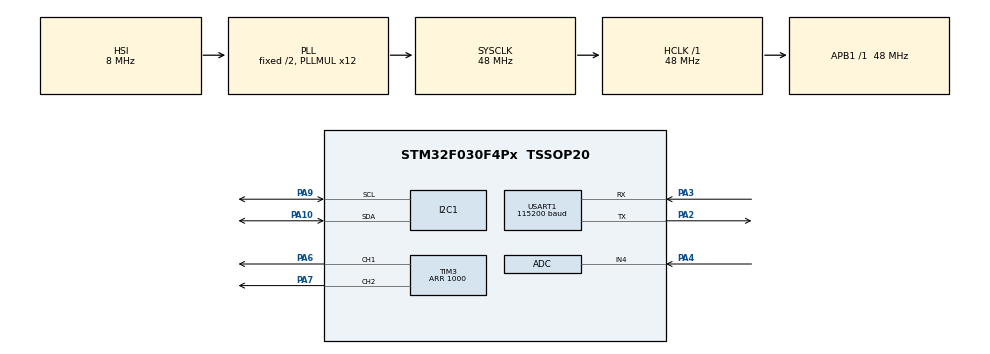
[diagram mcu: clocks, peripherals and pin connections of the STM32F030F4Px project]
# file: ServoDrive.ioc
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ADC.ContinuousConvMode=DISABLE
Dma.ADC.0.Direction=DMA_PERIPH_TO_MEMORY
Dma.ADC.0.Instance=DMA1_Channel1
Dma.ADC.0.MemDataAlignment=DMA_MDATAALIGN_HALFWORD
Dma.ADC.0.MemInc=DMA_MINC_ENABLE
Dma.ADC.0.Mode=DMA_CIRCULAR
Dma.ADC.0.PeriphDataAlignment=DMA_PDATAALIGN_HALFWORD
Dma.ADC.0.PeriphInc=DMA_PINC_DISABLE
Dma.ADC.0.Priority=DMA_PRIORITY_LOW
Dma.Request0=ADC
Mcu.Family=STM32F0
Mcu.Name=STM32F030F4Px
Mcu.Package=TSSOP20
NVIC.DMA1_Channel1_IRQn=true\:0\:0\:false\:false\:true\:false\:true\:true
NVIC.I2C1_IRQn=true\:0\:0\:false\:false\:true\:true\:true\:true
NVIC.TIM14_IRQn=true\:3\:0\:true\:false\:true\:true\:true\:true
PA10.Mode=I2C
PA10.Signal=I2C1_SDA
PA13.Mode=Serial_Wire
PA13.Signal=SYS_SWDIO
PA14.Mode=Serial_Wire
PA14.Signal=SYS_SWCLK
PA2.Mode=Asynchronous
PA2.Signal=USART1_TX
PA3.Mode=Asynchronous
PA3.Signal=USART1_RX
PA4.Mode=IN4
PA4.Signal=ADC_IN4
PA6.Signal=S_TIM3_CH1
PA7.Signal=S_TIM3_CH2
PA9.Mode=I2C
PA9.Signal=I2C1_SCL
ProjectManager.HeapSize=0x200
ProjectManager.StackSize=0x400
ProjectManager.TargetToolchain=Makefile
RCC.AHBFreq_Value=48000000
RCC.APB1Freq_Value=48000000
RCC.APB1TimFreq_Value=48000000
RCC.HCLKFreq_Value=48000000
RCC.PLLMUL=RCC_PLL_MUL12
RCC.SYSCLKFreq_VALUE=48000000
RCC.SYSCLKSource=RCC_SYSCLKSOURCE_PLLCLK
SH.S_TIM3_CH1.0=TIM3_CH1,PWM Generation1 CH1
SH.S_TIM3_CH2.0=TIM3_CH2,PWM Generation2 CH2
TIM14.Period=1000
TIM14.Prescaler=47
TIM3.Channel-PWM\ Generation1\ CH1=TIM_CHANNEL_1
TIM3.Channel-PWM\ Generation2\ CH2=TIM_CHANNEL_2
TIM3.Period=1000
USART1.BaudRate=115200
USART1.VirtualMode-Asynchronous=VM_ASYNC
VP_TIM14_VS_ClockSourceINT.Mode=Enable_Timer
board=custom

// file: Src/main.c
/* USER CODE BEGIN Header */
/**
  ******************************************************************************
  * @file           : main.c
  * @brief          : Main program body
  ******************************************************************************
  * @attention
  *
  * Copyright (c) 2022 STMicroelectronics.
  * All rights reserved.
  *
  * This software is licensed under terms that can be found in the LICENSE file
  * in the root directory of this software component.
  * If no LICENSE file comes with this software, it is provided AS-IS.
  *
  ******************************************************************************
  */
/* USER CODE END Header */
#include "main.h"
#include "adc.h"
#include "dma.h"
#include "i2c.h"
#include "tim.h"
#include "usart.h"
#include "gpio.h"

/* USER CODE BEGIN Includes */
// #include <stdio.h>
#include "common_inc.h"
/* USER CODE END Includes */

void SystemClock_Config(void);

/* USER CODE BEGIN 0 */
int _write(int fd, char *ch, int len)
{
  int i;
  /* for(i=0;i<len;i++)
  {
    while(LL_USART_IsActiveFlag_TXE(USART1)==0)
    {}
     LL_USART_TransmitData8(USART1, ch[i]);
     //while(!LL_USART_IsActiveFlag_TC(USART1));
  } */
  HAL_UART_Transmit(&huart1, (uint8_t*)ch, len, 0xFFFF);

  return len;
}
/* USER CODE END 0 */

int main(void)
{

  /* MCU Configuration--------------------------------------------------------*/

  /* Reset of all peripherals, Initializes the Flash interface and the Systick. */
  HAL_Init();

  /* Configure the system clock */
  SystemClock_Config();

  /* Initialize all configured peripherals */
  MX_GPIO_Init();
  MX_DMA_Init();
  MX_USART1_UART_Init();
  MX_TIM3_Init();
  MX_ADC_Init();
  MX_I2C1_Init();
  MX_TIM14_Init();
  /* USER CODE BEGIN 2 */
  //printf("hello ServoDrive coming...\r\n");

  // LL_TIM_EnableIT_UPDATE(TIM14);
  // LL_TIM_EnableCounter(TIM14);
  Main();
  /* USER CODE END 2 */

  /* Infinite loop */
  /* USER CODE BEGIN WHILE */
  while (1)
  {
    //while(LL_USART_IsActiveFlag_TXE(USART1)==0);
    //LL_USART_TransmitData8(USART1, 'c');
    //while(!LL_USART_IsActiveFlag_TC(USART1));
    /* USER CODE END WHILE */

    /* USER CODE BEGIN 3 */
    //HAL_UART_Transmit(&huart1, (uint8_t*)"hello", 5, 0xFFFF);
  }
  /* USER CODE END 3 */
}

void SystemClock_Config(void)
{
  RCC_OscInitTypeDef RCC_OscInitStruct = {0};
  RCC_ClkInitTypeDef RCC_ClkInitStruct = {0};
  RCC_PeriphCLKInitTypeDef PeriphClkInit = {0};

  /** Initializes the RCC Oscillators according to the specified parameters
  * in the RCC_OscInitTypeDef structure.
  */
  RCC_OscInitStruct.OscillatorType = RCC_OSCILLATORTYPE_HSI|RCC_OSCILLATORTYPE_HSI14;
  RCC_OscInitStruct.HSIState = RCC_HSI_ON;
  RCC_OscInitStruct.HSI14State = RCC_HSI14_ON;
  RCC_OscInitStruct.HSICalibrationValue = RCC_HSICALIBRATION_DEFAULT;
  RCC_OscInitStruct.HSI14CalibrationValue = 16;
  RCC_OscInitStruct.PLL.PLLState = RCC_PLL_ON;
  RCC_OscInitStruct.PLL.PLLSource = RCC_PLLSOURCE_HSI;
  RCC_OscInitStruct.PLL.PLLMUL = RCC_PLL_MUL12;
  RCC_OscInitStruct.PLL.PREDIV = RCC_PREDIV_DIV1;
  if (HAL_RCC_OscConfig(&RCC_OscInitStruct) != HAL_OK)
  {
    Error_Handler();
  }

  /** Initializes the CPU, AHB and APB buses clocks
  */
  RCC_ClkInitStruct.ClockType = RCC_CLOCKTYPE_HCLK|RCC_CLOCKTYPE_SYSCLK
                              |RCC_CLOCKTYPE_PCLK1;
  RCC_ClkInitStruct.SYSCLKSource = RCC_SYSCLKSOURCE_PLLCLK;
  RCC_ClkInitStruct.AHBCLKDivider = RCC_SYSCLK_DIV1;
  RCC_ClkInitStruct.APB1CLKDivider = RCC_HCLK_DIV1;

  if (HAL_RCC_ClockConfig(&RCC_ClkInitStruct, FLASH_LATENCY_1) != HAL_OK)
  {
    Error_Handler();
  }
  PeriphClkInit.PeriphClockSelection = RCC_PERIPHCLK_USART1|RCC_PERIPHCLK_I2C1;
  PeriphClkInit.Usart1ClockSelection = RCC_USART1CLKSOURCE_PCLK1;
  PeriphClkInit.I2c1ClockSelection = RCC_I2C1CLKSOURCE_HSI;
  if (HAL_RCCEx_PeriphCLKConfig(&PeriphClkInit) != HAL_OK)
  {
    Error_Handler();
  }
}

void Error_Handler(void)
{
  __disable_irq();
  while (1)
  {
  }
}
